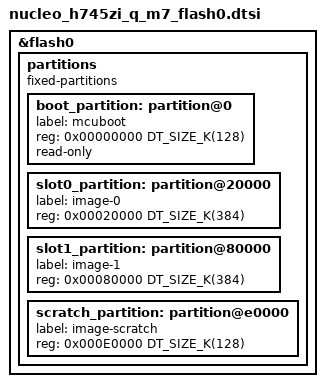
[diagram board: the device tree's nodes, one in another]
/**
 * @file      nucleo_h745zi_q_m7_flash0.dtsi
 * @brief     Nucleo STM32H745 flash0 overlay include
 *
 * Copyright joelguittet and mender-mcu-client contributors
 *
 * Licensed under the Apache License, Version 2.0 (the "License");
 * you may not use this file except in compliance with the License.
 * You may obtain a copy of the License at
 *
 *     http://www.apache.org/licenses/LICENSE-2.0
 *
 * Unless required by applicable law or agreed to in writing, software
 * distributed under the License is distributed on an "AS IS" BASIS,
 * WITHOUT WARRANTIES OR CONDITIONS OF ANY KIND, either express or implied.
 * See the License for the specific language governing permissions and
 * limitations under the License.
 */

&flash0 {
    partitions {
        compatible = "fixed-partitions";
        #address-cells = <1>;
        #size-cells = <1>;
        /* Bootloader slot: 128KB */
        boot_partition: partition@0 {
            label = "mcuboot";
            reg = <0x00000000 DT_SIZE_K(128)>;
            read-only;
        };
        /* Application slot: 384KB */
        slot0_partition: partition@20000 {
            label = "image-0";
            reg = <0x00020000 DT_SIZE_K(384)>;
        };
        /* Update slot: 384KB */
        slot1_partition: partition@80000 {
            label = "image-1";
            reg = <0x00080000 DT_SIZE_K(384)>;
        };
        /* Scratch slot: 128KB */
        scratch_partition: partition@e0000 {
            label = "image-scratch";
            reg = <0x000E0000 DT_SIZE_K(128)>;
        };
    };
};
